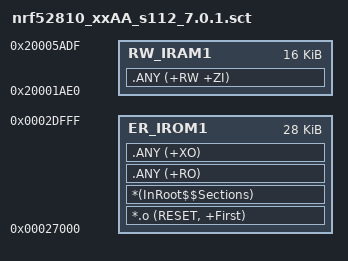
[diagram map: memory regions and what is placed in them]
; *************************************************************
; *** Scatter-Loading Description File generated by uVision ***
; *************************************************************

LR_IROM1 0x00027000 0x00007000  {    ; load region size_region
  ER_IROM1 0x00027000 0x00007000  {  ; load address = execution address
   *.o (RESET, +First)
   *(InRoot$$Sections)
   .ANY (+RO)
   .ANY (+XO)
  }
  ;RW_IRAM1 0x200022C8 0x00003D38  {  ; RW data keil工程的分区
  RW_IRAM1 0x20001AE0 0x00004000  {
   .ANY (+RW +ZI)
  }
}

